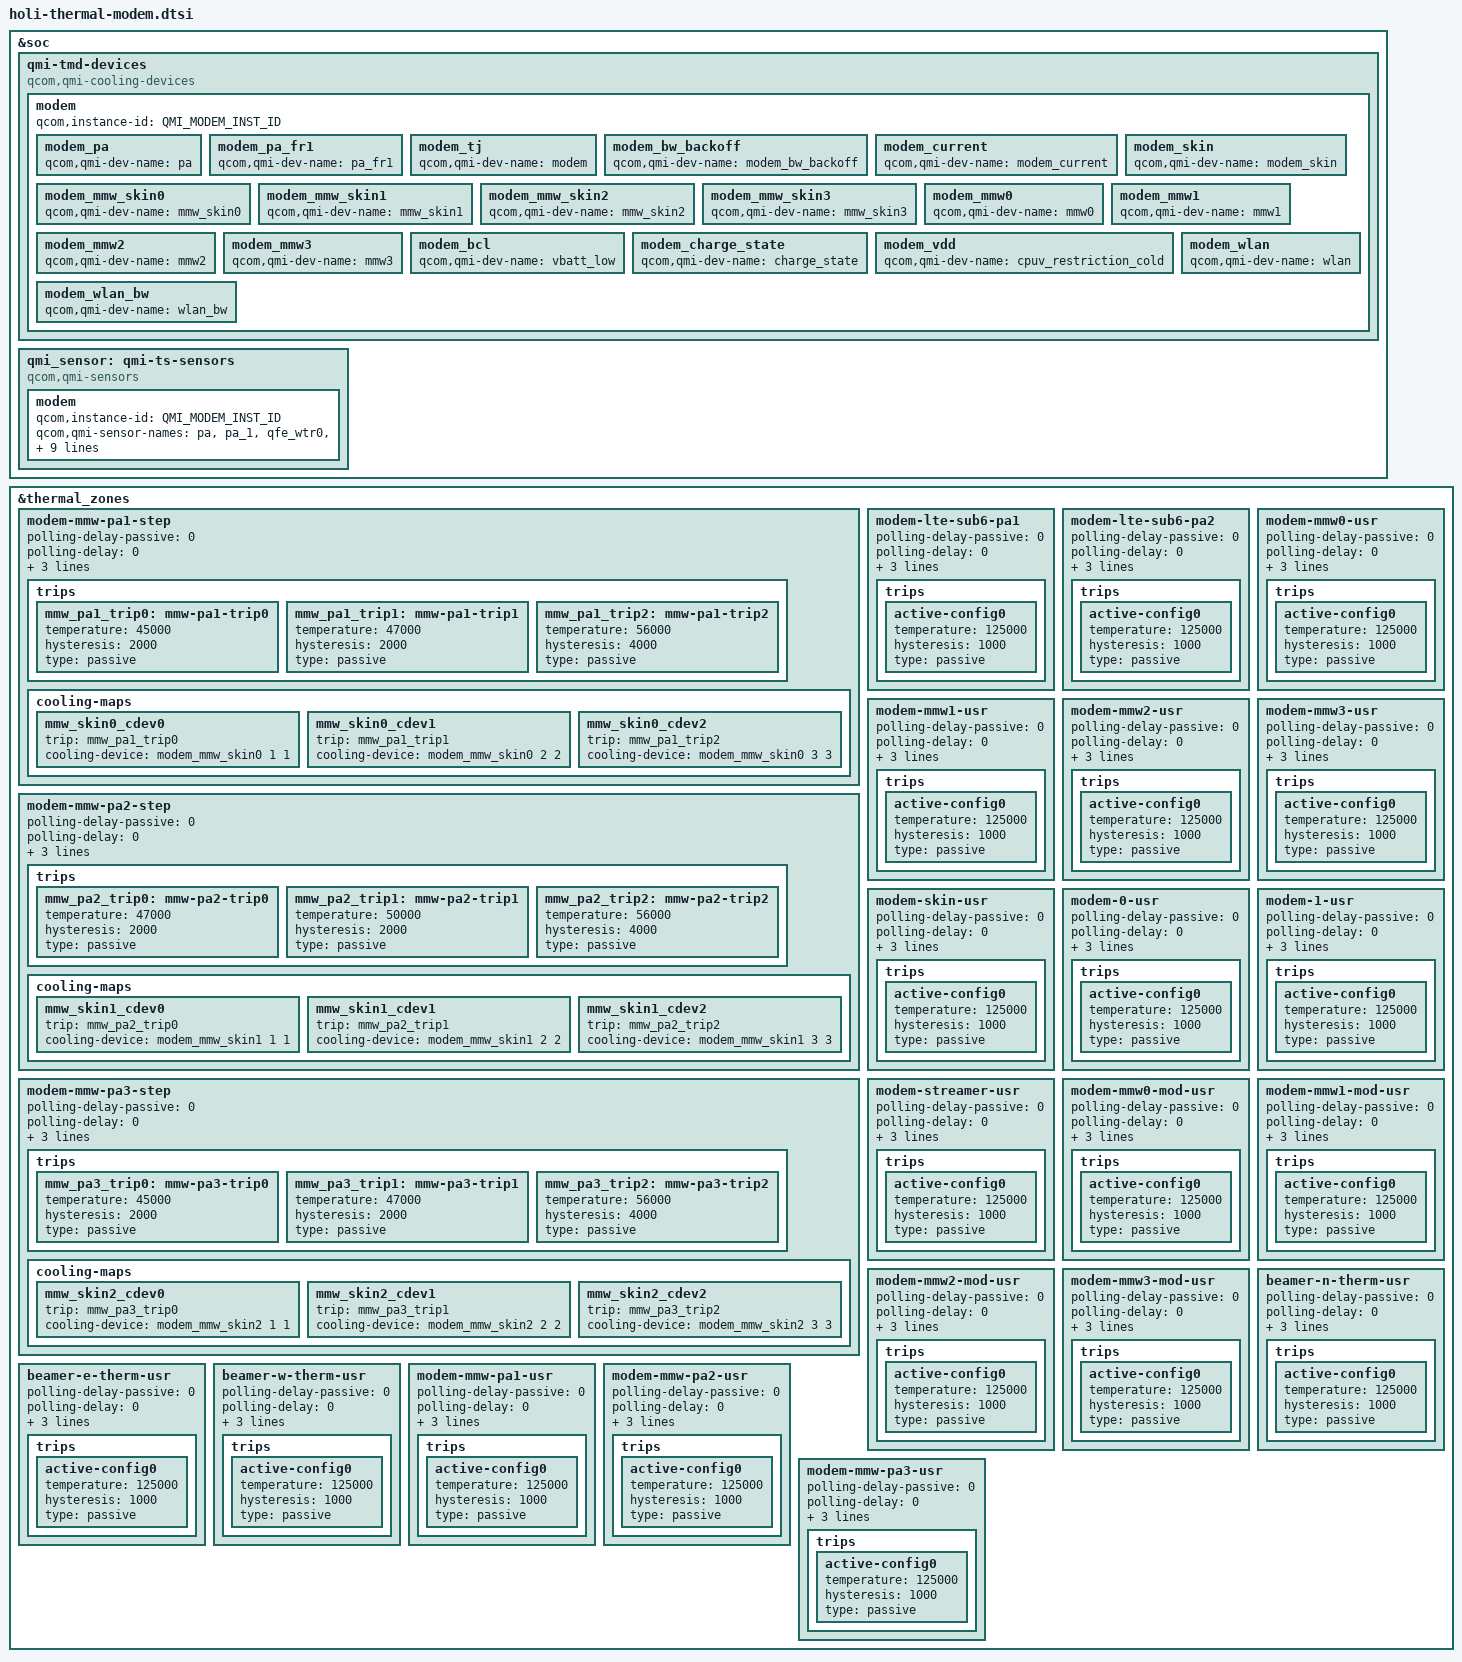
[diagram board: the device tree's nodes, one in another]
&soc {
	qmi-tmd-devices {
		compatible = "qcom,qmi-cooling-devices";

		modem {
			qcom,instance-id = <QMI_MODEM_INST_ID>;

			modem_pa: modem_pa {
				qcom,qmi-dev-name = "pa";
				#cooling-cells = <2>;
			};

			modem_pa_fr1: modem_pa_fr1 {
				qcom,qmi-dev-name = "pa_fr1";
				#cooling-cells = <2>;
			};

			modem_tj: modem_tj {
				qcom,qmi-dev-name = "modem";
				#cooling-cells = <2>;
			};

			modem_bw_backoff: modem_bw_backoff {
				qcom,qmi-dev-name = "modem_bw_backoff";
				#cooling-cells = <2>;
			};

			modem_current: modem_current {
				qcom,qmi-dev-name = "modem_current";
				#cooling-cells = <2>;
			};

			modem_skin: modem_skin {
				qcom,qmi-dev-name = "modem_skin";
				#cooling-cells = <2>;
			};

			modem_mmw_skin0: modem_mmw_skin0 {
				qcom,qmi-dev-name = "mmw_skin0";
				#cooling-cells = <2>;
			};

			modem_mmw_skin1: modem_mmw_skin1 {
				qcom,qmi-dev-name = "mmw_skin1";
				#cooling-cells = <2>;
			};

			modem_mmw_skin2: modem_mmw_skin2 {
				qcom,qmi-dev-name = "mmw_skin2";
				#cooling-cells = <2>;
			};

			modem_mmw_skin3: modem_mmw_skin3 {
				qcom,qmi-dev-name = "mmw_skin3";
				#cooling-cells = <2>;
			};

			modem_mmw0: modem_mmw0 {
				qcom,qmi-dev-name = "mmw0";
				#cooling-cells = <2>;
			};

			modem_mmw1: modem_mmw1 {
				qcom,qmi-dev-name = "mmw1";
				#cooling-cells = <2>;
			};

			modem_mmw2: modem_mmw2 {
				qcom,qmi-dev-name = "mmw2";
				#cooling-cells = <2>;
			};

			modem_mmw3: modem_mmw3 {
				qcom,qmi-dev-name = "mmw3";
				#cooling-cells = <2>;
			};

			modem_bcl: modem_bcl {
				qcom,qmi-dev-name = "vbatt_low";
				#cooling-cells = <2>;
			};

			modem_charge_state: modem_charge_state {
				qcom,qmi-dev-name = "charge_state";
				#cooling-cells = <2>;
			};

			modem_vdd: modem_vdd {
				qcom,qmi-dev-name = "cpuv_restriction_cold";
				#cooling-cells = <2>;
			};

			modem_wlan: modem_wlan {
				qcom,qmi-dev-name = "wlan";
				#cooling-cells = <2>;
			};

			modem_wlan_bw: modem_wlan_bw {
				qcom,qmi-dev-name = "wlan_bw";
				#cooling-cells = <2>;
			};
		};
	};

	qmi_sensor: qmi-ts-sensors {
		compatible = "qcom,qmi-sensors";
		#thermal-sensor-cells = <1>;

		modem {
			qcom,instance-id = <QMI_MODEM_INST_ID>;
			qcom,qmi-sensor-names = "pa",
						"pa_1",
						"qfe_wtr0",
						"modem_tsens",
						"qfe_mmw0",
						"qfe_mmw1",
						"qfe_mmw2",
						"qfe_mmw3",
						"xo_therm",
						"qfe_mmw_streamer0",
						"qfe_mmw0_mod",
						"qfe_mmw1_mod",
						"qfe_mmw2_mod",
						"qfe_mmw3_mod",
						"qfe_ret_pa0",
						"qfe_wtr_pa0",
						"qfe_wtr_pa1",
						"qfe_wtr_pa2",
						"qfe_wtr_pa3",
						"modem_tsens1",
						"beamer_n_therm",
						"beamer_e_therm",
						"beamer_w_therm",
						"qfe_ret_pa0_fr1",
						"qfe_wtr_pa0_fr1",
						"mmw_pa1",
						"mmw_pa2",
						"mmw_pa3",
						"qfe_wtr0_fr1";
		};
	};
};

&thermal_zones {
	modem-mmw-pa1-step {
		polling-delay-passive = <0>;
		polling-delay = <0>;
		thermal-governor = "step_wise";
		thermal-sensors = <&qmi_sensor
				(QMI_MODEM_INST_ID+QMI_MMW_PA1)>;
		trips {
			mmw_pa1_trip0: mmw-pa1-trip0 {
				temperature = <45000>;
				hysteresis = <2000>;
				type = "passive";
			};

			mmw_pa1_trip1: mmw-pa1-trip1 {
				temperature = <47000>;
				hysteresis = <2000>;
				type = "passive";
			};

			mmw_pa1_trip2: mmw-pa1-trip2 {
				temperature = <56000>;
				hysteresis = <4000>;
				type = "passive";
			};
		};

		cooling-maps {
			mmw_skin0_cdev0 {
				trip = <&mmw_pa1_trip0>;
				cooling-device = <&modem_mmw_skin0 1 1>;
			};

			mmw_skin0_cdev1 {
				trip = <&mmw_pa1_trip1>;
				cooling-device = <&modem_mmw_skin0 2 2>;
			};

			mmw_skin0_cdev2 {
				trip = <&mmw_pa1_trip2>;
				cooling-device = <&modem_mmw_skin0 3 3>;
			};
		};
	};

	modem-mmw-pa2-step {
		polling-delay-passive = <0>;
		polling-delay = <0>;
		thermal-governor = "step_wise";
		thermal-sensors = <&qmi_sensor
				(QMI_MODEM_INST_ID+QMI_MMW_PA2)>;
		trips {
			mmw_pa2_trip0: mmw-pa2-trip0 {
				temperature = <47000>;
				hysteresis = <2000>;
				type = "passive";
			};

			mmw_pa2_trip1: mmw-pa2-trip1 {
				temperature = <50000>;
				hysteresis = <2000>;
				type = "passive";
			};

			mmw_pa2_trip2: mmw-pa2-trip2 {
				temperature = <56000>;
				hysteresis = <4000>;
				type = "passive";
			};
		};

		cooling-maps {
			mmw_skin1_cdev0 {
				trip = <&mmw_pa2_trip0>;
				cooling-device = <&modem_mmw_skin1 1 1>;
			};

			mmw_skin1_cdev1 {
				trip = <&mmw_pa2_trip1>;
				cooling-device = <&modem_mmw_skin1 2 2>;
			};

			mmw_skin1_cdev2 {
				trip = <&mmw_pa2_trip2>;
				cooling-device = <&modem_mmw_skin1 3 3>;
			};
		};
	};

	modem-mmw-pa3-step {
		polling-delay-passive = <0>;
		polling-delay = <0>;
		thermal-governor = "step_wise";
		thermal-sensors = <&qmi_sensor
				(QMI_MODEM_INST_ID+QMI_MMW_PA3)>;
		trips {
			mmw_pa3_trip0: mmw-pa3-trip0 {
				temperature = <45000>;
				hysteresis = <2000>;
				type = "passive";
			};

			mmw_pa3_trip1: mmw-pa3-trip1 {
				temperature = <47000>;
				hysteresis = <2000>;
				type = "passive";
			};

			mmw_pa3_trip2: mmw-pa3-trip2 {
				temperature = <56000>;
				hysteresis = <4000>;
				type = "passive";
			};
		};

		cooling-maps {
			mmw_skin2_cdev0 {
				trip = <&mmw_pa3_trip0>;
				cooling-device = <&modem_mmw_skin2 1 1>;
			};

			mmw_skin2_cdev1 {
				trip = <&mmw_pa3_trip1>;
				cooling-device = <&modem_mmw_skin2 2 2>;
			};

			mmw_skin2_cdev2 {
				trip = <&mmw_pa3_trip2>;
				cooling-device = <&modem_mmw_skin2 3 3>;
			};
		};
	};

	modem-lte-sub6-pa1 {
		polling-delay-passive = <0>;
		polling-delay = <0>;
		thermal-governor = "user_space";
		thermal-sensors = <&qmi_sensor
				(QMI_MODEM_INST_ID+QMI_PA)>;
		trips {
			active-config0 {
				temperature = <125000>;
				hysteresis = <1000>;
				type = "passive";
			};
		};
	};

	modem-lte-sub6-pa2 {
		polling-delay-passive = <0>;
		polling-delay = <0>;
		thermal-governor = "user_space";
		thermal-sensors = <&qmi_sensor
				(QMI_MODEM_INST_ID+QMI_PA_1)>;
		trips {
			active-config0 {
				temperature = <125000>;
				hysteresis = <1000>;
				type = "passive";
			};
		};
	};

	modem-mmw0-usr {
		polling-delay-passive = <0>;
		polling-delay = <0>;
		thermal-governor = "user_space";
		thermal-sensors = <&qmi_sensor
				(QMI_MODEM_INST_ID+QMI_QFE_MMW_0)>;
		trips {
			active-config0 {
				temperature = <125000>;
				hysteresis = <1000>;
				type = "passive";
			};
		};
	};

	modem-mmw1-usr {
		polling-delay-passive = <0>;
		polling-delay = <0>;
		thermal-governor = "user_space";
		thermal-sensors = <&qmi_sensor
				(QMI_MODEM_INST_ID+QMI_QFE_MMW_1)>;
		trips {
			active-config0 {
				temperature = <125000>;
				hysteresis = <1000>;
				type = "passive";
			};
		};
	};

	modem-mmw2-usr {
		polling-delay-passive = <0>;
		polling-delay = <0>;
		thermal-governor = "user_space";
		thermal-sensors = <&qmi_sensor
				(QMI_MODEM_INST_ID+QMI_QFE_MMW_2)>;
		trips {
			active-config0 {
				temperature = <125000>;
				hysteresis = <1000>;
				type = "passive";
			};
		};
	};

	modem-mmw3-usr {
		polling-delay-passive = <0>;
		polling-delay = <0>;
		thermal-governor = "user_space";
		thermal-sensors = <&qmi_sensor
				(QMI_MODEM_INST_ID+QMI_QFE_MMW_3)>;
		trips {
			active-config0 {
				temperature = <125000>;
				hysteresis = <1000>;
				type = "passive";
			};
		};
	};

	modem-skin-usr {
		polling-delay-passive = <0>;
		polling-delay = <0>;
		thermal-governor = "user_space";
		thermal-sensors = <&qmi_sensor
				(QMI_MODEM_INST_ID+QMI_XO_THERM)>;
		trips {
			active-config0 {
				temperature = <125000>;
				hysteresis = <1000>;
				type = "passive";
			};
		};
	};

	modem-0-usr {
		polling-delay-passive = <0>;
		polling-delay = <0>;
		thermal-governor = "user_space";
		thermal-sensors = <&qmi_sensor
				(QMI_MODEM_INST_ID+QMI_MODEM_TSENS)>;
		trips {
			active-config0 {
				temperature = <125000>;
				hysteresis = <1000>;
				type = "passive";
			};
		};
	};

	modem-1-usr {
		polling-delay-passive = <0>;
		polling-delay = <0>;
		thermal-governor = "user_space";
		thermal-sensors = <&qmi_sensor
				(QMI_MODEM_INST_ID+QMI_MODEM_TSENS_1)>;
		trips {
			active-config0 {
				temperature = <125000>;
				hysteresis = <1000>;
				type = "passive";
			};
		};
	};

	modem-streamer-usr {
		polling-delay-passive = <0>;
		polling-delay = <0>;
		thermal-governor = "user_space";
		thermal-sensors = <&qmi_sensor
				(QMI_MODEM_INST_ID+QMI_QFE_MMW_STREAMER_0)>;
		trips {
			active-config0 {
				temperature = <125000>;
				hysteresis = <1000>;
				type = "passive";
			};
		};
	};

	modem-mmw0-mod-usr {
		polling-delay-passive = <0>;
		polling-delay = <0>;
		thermal-governor = "user_space";
		thermal-sensors = <&qmi_sensor
				(QMI_MODEM_INST_ID+QMI_QFE_MMW_0_MOD)>;
		trips {
			active-config0 {
				temperature = <125000>;
				hysteresis = <1000>;
				type = "passive";
			};
		};
	};

	modem-mmw1-mod-usr {
		polling-delay-passive = <0>;
		polling-delay = <0>;
		thermal-governor = "user_space";
		thermal-sensors = <&qmi_sensor
				(QMI_MODEM_INST_ID+QMI_QFE_MMW_1_MOD)>;
		trips {
			active-config0 {
				temperature = <125000>;
				hysteresis = <1000>;
				type = "passive";
			};
		};
	};

	modem-mmw2-mod-usr {
		polling-delay-passive = <0>;
		polling-delay = <0>;
		thermal-governor = "user_space";
		thermal-sensors = <&qmi_sensor
				(QMI_MODEM_INST_ID+QMI_QFE_MMW_2_MOD)>;
		trips {
			active-config0 {
				temperature = <125000>;
				hysteresis = <1000>;
				type = "passive";
			};
		};
	};

	modem-mmw3-mod-usr {
		polling-delay-passive = <0>;
		polling-delay = <0>;
		thermal-governor = "user_space";
		thermal-sensors = <&qmi_sensor
				(QMI_MODEM_INST_ID+QMI_QFE_MMW_3_MOD)>;
		trips {
			active-config0 {
				temperature = <125000>;
				hysteresis = <1000>;
				type = "passive";
			};
		};
	};

	beamer-n-therm-usr {
		polling-delay-passive = <0>;
		polling-delay = <0>;
		thermal-governor = "user_space";
		thermal-sensors = <&qmi_sensor
				(QMI_MODEM_INST_ID+QMI_BEAMER_N_THERM)>;
		trips {
			active-config0 {
				temperature = <125000>;
				hysteresis = <1000>;
				type = "passive";
			};
		};
	};

	beamer-e-therm-usr {
		polling-delay-passive = <0>;
		polling-delay = <0>;
		thermal-governor = "user_space";
		thermal-sensors = <&qmi_sensor
				(QMI_MODEM_INST_ID+QMI_BEAMER_E_THERM)>;
		trips {
			active-config0 {
				temperature = <125000>;
				hysteresis = <1000>;
				type = "passive";
			};
		};
	};

	beamer-w-therm-usr {
		polling-delay-passive = <0>;
		polling-delay = <0>;
		thermal-governor = "user_space";
		thermal-sensors = <&qmi_sensor
				(QMI_MODEM_INST_ID+QMI_BEAMER_W_THERM)>;
		trips {
			active-config0 {
				temperature = <125000>;
				hysteresis = <1000>;
				type = "passive";
			};
		};
	};

	modem-mmw-pa1-usr {
		polling-delay-passive = <0>;
		polling-delay = <0>;
		thermal-governor = "user_space";
		thermal-sensors = <&qmi_sensor
				(QMI_MODEM_INST_ID+QMI_MMW_PA1)>;
		trips {
			active-config0 {
				temperature = <125000>;
				hysteresis = <1000>;
				type = "passive";
			};
		};
	};

	modem-mmw-pa2-usr {
		polling-delay-passive = <0>;
		polling-delay = <0>;
		thermal-governor = "user_space";
		thermal-sensors = <&qmi_sensor
				(QMI_MODEM_INST_ID+QMI_MMW_PA2)>;
		trips {
			active-config0 {
				temperature = <125000>;
				hysteresis = <1000>;
				type = "passive";
			};
		};
	};

	modem-mmw-pa3-usr {
		polling-delay-passive = <0>;
		polling-delay = <0>;
		thermal-governor = "user_space";
		thermal-sensors = <&qmi_sensor
				(QMI_MODEM_INST_ID+QMI_MMW_PA3)>;
		trips {
			active-config0 {
				temperature = <125000>;
				hysteresis = <1000>;
				type = "passive";
			};
		};
	};
};
